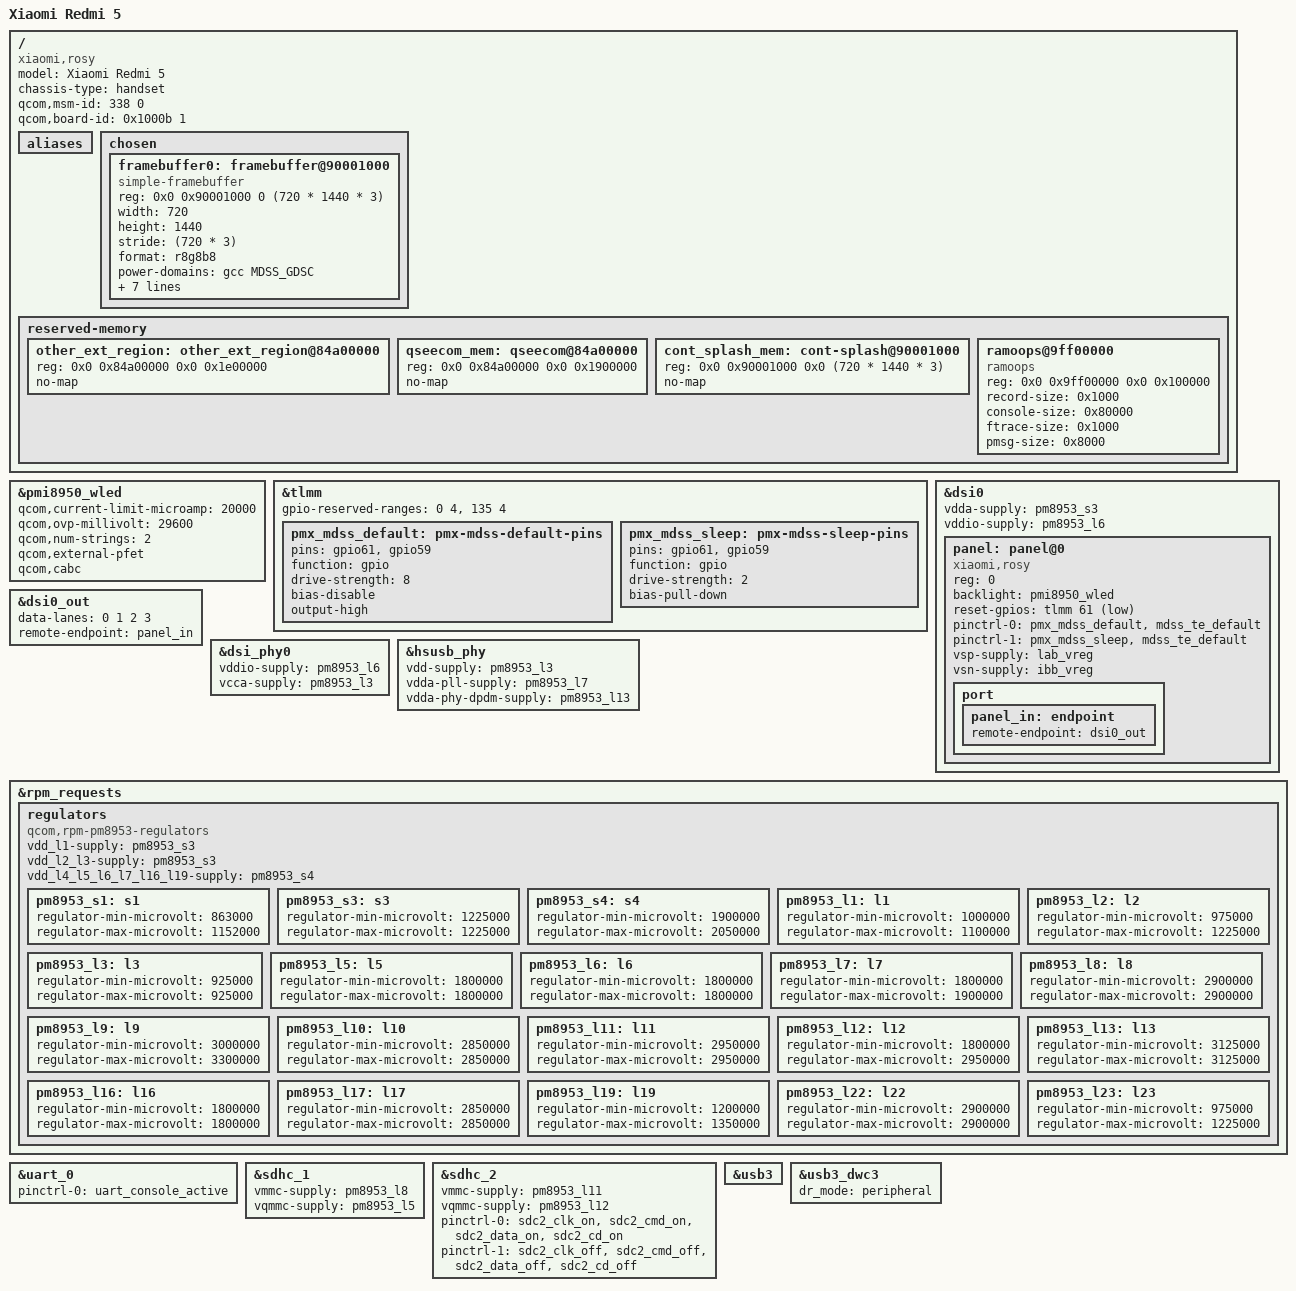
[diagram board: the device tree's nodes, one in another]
// SPDX-License-Identifier: GPL-2.0-only

/dts-v1/;

#include "msm8953.dtsi"
#include "pm8953.dtsi"
#include "pmi8950.dtsi"

/{
    model = "Xiaomi Redmi 5";
    compatible = "xiaomi,rosy", "qcom,sdm450";
    chassis-type = "handset";
    qcom,msm-id = <338 0>;
	qcom,board-id = <0x1000b 1>;

    aliases {

    };

    chosen {
        #address-cells = <2>;
		#size-cells = <2>;
		ranges;

        framebuffer0: framebuffer@90001000 {
			compatible = "simple-framebuffer";
			reg = <0x0 0x90001000 0 (720 * 1440 * 3)>;

			width = <720>;
			height = <1440>;
			stride = <(720 * 3)>;
			format = "r8g8b8";

			power-domains = <&gcc MDSS_GDSC>;

			clocks = <&gcc GCC_MDSS_AHB_CLK>,
				 <&gcc GCC_MDSS_AXI_CLK>,
				 <&gcc GCC_MDSS_VSYNC_CLK>,
				 <&gcc GCC_MDSS_MDP_CLK>,
				 <&gcc GCC_MDSS_BYTE0_CLK>,
				 <&gcc GCC_MDSS_PCLK0_CLK>,
				 <&gcc GCC_MDSS_ESC0_CLK>;
		};
    };

    reserved-memory {
		/delete-node/memory@85b00000;

		other_ext_region: other_ext_region@84a00000 {
			reg = <0x0 0x84a00000 0x0 0x1e00000>;
			no-map;
		};

		qseecom_mem: qseecom@84a00000 {
			reg = <0x0 0x84a00000 0x0 0x1900000>;
			no-map;
		};

		cont_splash_mem: cont-splash@90001000 {
			reg = <0x0 0x90001000 0x0 (720 * 1440 * 3)>;
			no-map;
		};

		ramoops@9ff00000 {
			compatible = "ramoops";
			reg = <0x0 0x9ff00000 0x0 0x100000>;
			record-size = <0x1000>;
			console-size = <0x80000>;
			ftrace-size = <0x1000>;
			pmsg-size = <0x8000>;
		};
	};
};

&pmi8950_wled {
	qcom,current-limit-microamp = <20000>;
	qcom,ovp-millivolt = <29600>;
	qcom,num-strings = <2>;
	qcom,external-pfet;
	qcom,cabc;

	status = "okay";
};

&tlmm {
	gpio-reserved-ranges = <0 4>, <135 4>;

	pmx_mdss_default: pmx-mdss-default-pins {
		pins = "gpio61", "gpio59";
		function = "gpio";
		drive-strength = <8>;
		bias-disable;
		output-high;
	};

	pmx_mdss_sleep: pmx-mdss-sleep-pins {
		pins = "gpio61", "gpio59";
		function = "gpio";
		drive-strength = <2>;
		bias-pull-down;
	};
};

&dsi0 {
    vdda-supply = <&pm8953_s3>;
	vddio-supply = <&pm8953_l6>;

	panel: panel@0 {
		compatible = "xiaomi,rosy";
		reg = <0>;

		backlight = <&pmi8950_wled>;

		reset-gpios = <&tlmm 61 GPIO_ACTIVE_LOW>;

        pinctrl-names = "default", "sleep";
		pinctrl-0 = <&pmx_mdss_default &mdss_te_default>;
		pinctrl-1 = <&pmx_mdss_sleep &mdss_te_default>;

        vsp-supply = <&lab_vreg>;
		vsn-supply = <&ibb_vreg>;

		port {
			panel_in: endpoint {
				remote-endpoint = <&dsi0_out>;
			};
		};
	};
};

&dsi0_out {
	data-lanes = <0 1 2 3>;
	remote-endpoint = <&panel_in>;
};

&dsi_phy0 {
        vddio-supply = <&pm8953_l6>;
        vcca-supply = <&pm8953_l3>;
};

&hsusb_phy {
	vdd-supply = <&pm8953_l3>;
	vdda-pll-supply = <&pm8953_l7>;
	vdda-phy-dpdm-supply = <&pm8953_l13>;

	status = "okay";
};

&rpm_requests {
	regulators {
        compatible = "qcom,rpm-pm8953-regulators";
        vdd_l1-supply = <&pm8953_s3>;
		vdd_l2_l3-supply = <&pm8953_s3>;
		vdd_l4_l5_l6_l7_l16_l19-supply = <&pm8953_s4>;

		pm8953_s1: s1 {
			regulator-min-microvolt = <863000>;
			regulator-max-microvolt = <1152000>;
		};

		pm8953_s3: s3 {
			regulator-min-microvolt = <1225000>;
			regulator-max-microvolt = <1225000>;
		};

		pm8953_s4: s4 {
			regulator-min-microvolt = <1900000>;
			regulator-max-microvolt = <2050000>;
		};

		pm8953_l1: l1 {
			regulator-min-microvolt = <1000000>;
			regulator-max-microvolt = <1100000>;
		};

		pm8953_l2: l2 {
			regulator-min-microvolt = <975000>;
			regulator-max-microvolt = <1225000>;
		};

		pm8953_l3: l3 {
			regulator-min-microvolt = <925000>;
			regulator-max-microvolt = <925000>;
		};

		pm8953_l5: l5 {
			regulator-min-microvolt = <1800000>;
			regulator-max-microvolt = <1800000>;
		};

		pm8953_l6: l6 {
			regulator-min-microvolt = <1800000>;
			regulator-max-microvolt = <1800000>;
		};

		pm8953_l7: l7 {
			regulator-min-microvolt = <1800000>;
			regulator-max-microvolt = <1900000>;
		};

		pm8953_l8: l8 {
			regulator-min-microvolt = <2900000>;
			regulator-max-microvolt = <2900000>;
		};

		pm8953_l9: l9 {
			regulator-min-microvolt = <3000000>;
			regulator-max-microvolt = <3300000>;
		};

		pm8953_l10: l10 {
			regulator-min-microvolt = <2850000>;
			regulator-max-microvolt = <2850000>;
		};

		pm8953_l11: l11 {
			regulator-min-microvolt = <2950000>;
			regulator-max-microvolt = <2950000>;
		};

		pm8953_l12: l12 {
			regulator-min-microvolt = <1800000>;
			regulator-max-microvolt = <2950000>;
		};

		pm8953_l13: l13 {
			regulator-min-microvolt = <3125000>;
			regulator-max-microvolt = <3125000>;
		};
		
		pm8953_l16: l16 {
			regulator-min-microvolt = <1800000>;
			regulator-max-microvolt = <1800000>;
		};
		
		pm8953_l17: l17 {
			regulator-min-microvolt = <2850000>;
			regulator-max-microvolt = <2850000>;
		};
		
		pm8953_l19: l19 {
			regulator-min-microvolt = <1200000>;
			regulator-max-microvolt = <1350000>;
		};
		
		pm8953_l22: l22 {
			regulator-min-microvolt = <2900000>;
			regulator-max-microvolt = <2900000>;
		};
		
		pm8953_l23: l23 {
			regulator-min-microvolt = <975000>;
			regulator-max-microvolt = <1225000>;
		};
    };
};

&uart_0 {
	pinctrl-names = "default";
	pinctrl-0 = <&uart_console_active>;

	status = "okay";
};

&sdhc_1 {
	vmmc-supply = <&pm8953_l8>;
	vqmmc-supply = <&pm8953_l5>;

	status = "okay";
};

&sdhc_2 {
	vmmc-supply = <&pm8953_l11>;
	vqmmc-supply = <&pm8953_l12>;

	pinctrl-names = "default", "sleep";
	pinctrl-0 = <&sdc2_clk_on &sdc2_cmd_on &sdc2_data_on &sdc2_cd_on>;
	pinctrl-1 = <&sdc2_clk_off &sdc2_cmd_off &sdc2_data_off &sdc2_cd_off>;

	status = "okay";
};

&usb3 {
	status = "okay";
};

&usb3_dwc3 {
	dr_mode = "peripheral";
};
